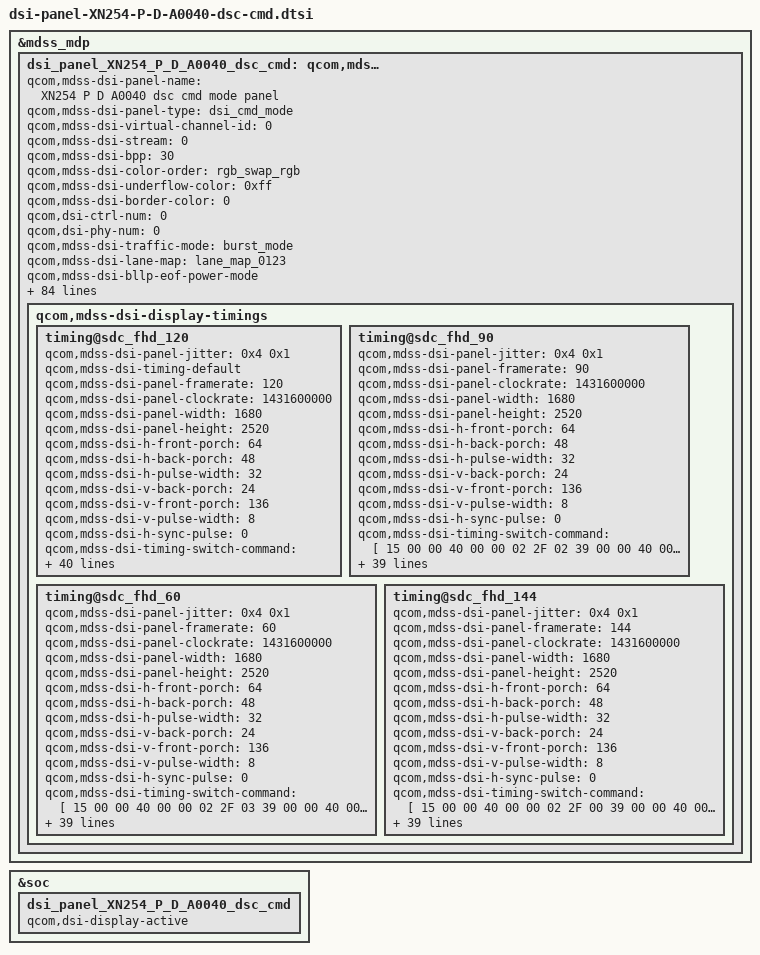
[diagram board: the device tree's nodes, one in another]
&mdss_mdp {
	dsi_panel_XN254_P_D_A0040_dsc_cmd: qcom,mdss_dsi_panel_XN254_P_D_A0040_dsc_cmd {
		qcom,mdss-dsi-panel-name = "XN254 P D A0040 dsc cmd mode panel";
		qcom,mdss-dsi-panel-type = "dsi_cmd_mode";
		qcom,mdss-dsi-virtual-channel-id = <0>;
		qcom,mdss-dsi-stream = <0>;
		qcom,mdss-dsi-bpp = <30>;
		qcom,mdss-dsi-color-order = "rgb_swap_rgb";
		qcom,mdss-dsi-underflow-color = <0xff>;
		qcom,mdss-dsi-border-color = <0>;
		qcom,dsi-ctrl-num = <0>;
		qcom,dsi-phy-num = <0>;
		qcom,mdss-dsi-traffic-mode = "burst_mode";
		qcom,mdss-dsi-lane-map = "lane_map_0123";
		qcom,mdss-dsi-bllp-eof-power-mode;
		qcom,mdss-dsi-bllp-power-mode;
		qcom,mdss-dsi-lane-0-state;
		qcom,mdss-dsi-lane-1-state;
		qcom,mdss-dsi-lane-2-state;
		qcom,mdss-dsi-lane-3-state;
		qcom,mdss-dsi-dma-trigger = "trigger_sw";
		qcom,mdss-dsi-dma-schedule-line = <1>;
		qcom,mdss-dsi-dma-schedule-window = <10>;
		qcom,mdss-dsi-mdp-trigger = "none";
		qcom,mdss-dsi-reset-sequence = <1 2>, <0 5>, <1 25>;
		qcom,mdss-dsi-te-pin-select = <1>;
		qcom,mdss-dsi-te-dcs-command = <1>;
		qcom,mdss-pan-physical-width-dimension = <124>;
		qcom,mdss-pan-physical-height-dimension = <186>;
		qcom,mdss-dsi-init-delay-us = <1000>;
		qcom,mdss-dsi-te-check-enable;
		qcom,mdss-dsi-te-using-te-pin;
		//qcom,mdss-dsi-lp11-init;
		qcom,mdss-dsi-wr-mem-start = <0x2c>;
		qcom,mdss-dsi-wr-mem-continue = <0x3c>;
		qcom,mdss-dsi-panel-jitter = <0x4 0x1>;
		qcom,mdss-bl-high2bit;
		/* HDR Setting */
		//qcom,mdss-dsi-panel-hdr-enabled;
		//qcom,mdss-dsi-panel-hdr-color-primaries = <15635 16450 34000 16000 13250 34500 7500 3000>;
		//update for [MPC15]android.mediapc.cts.PerformanceClassTest#testDisplayHdr pass
		//qcom,mdss-dsi-panel-peak-brightness = <5400000>;
		//qcom,mdss-dsi-panel-peak-brightness = <20000000>;
		//qcom,mdss-dsi-panel-average-brightness = <2000000>;
		//qcom,mdss-dsi-panel-blackness-level = <4000>;


		qcom,mdss-dsi-display-timings {
			timing@sdc_fhd_120 {
				#include "dsi-panel-XN254-P-D-A0040-loading-effect.dtsi"
				//qcom,mdss-mdp-transfer-time-us = <6900>;
				qcom,mdss-dsi-panel-jitter = <0x4 0x1>;
				qcom,mdss-dsi-timing-default;
				qcom,mdss-dsi-panel-framerate = <120>;
				qcom,mdss-dsi-panel-clockrate = <1431600000>;
				qcom,mdss-dsi-panel-width = <1680>;
				qcom,mdss-dsi-panel-height = <2520>;

				qcom,mdss-dsi-h-front-porch = <64>;
				qcom,mdss-dsi-h-back-porch = <48>;
				qcom,mdss-dsi-h-pulse-width = <32>;
				qcom,mdss-dsi-v-back-porch = <24>;
				qcom,mdss-dsi-v-front-porch = <136>;
				qcom,mdss-dsi-v-pulse-width = <8>;
				qcom,mdss-dsi-h-sync-pulse = <0>;

				qcom,mdss-dsi-timing-switch-command = [
					15 00 00 40 00 00 02 2F 01
					39 00 00 40 00 00 06 F0 55 AA 52 08 00
					15 00 00 40 00 00 02 6F 41
					15 00 00 00 00 00 02 BE 4B
				];

				qcom,mdss-dsi-timing-switch-v2-command = [
					15 00 00 40 00 00 02 2F 01
					39 00 00 40 00 00 06 F0 55 AA 52 08 00
					15 00 00 40 00 00 02 6F 41
					15 00 00 40 00 00 02 BE 4B
					39 00 00 40 00 00 06 F0 55 AA 52 08 08
					15 00 00 40 00 00 02 6F 10
					39 00 00 40 00 00 11 B7 00 00 00 00 00 00 00 00 00 00 00 00 05 DC 05 DC
					15 00 00 40 00 00 02 6F 20
					39 00 00 00 00 00 0F B7 06 FE 06 FE 07 58 07 58 07 A8 07 A8 08 00
				];

				qcom,mdss-dsi-on-command = [
					39 00 00 40 00 00 06 F0 55 AA 52 08 01
					39 00 00 40 00 00 06 C5 01 06 06 06 06
					39 00 00 40 00 00 06 F0 55 AA 52 08 01
					15 00 00 40 00 00 02 6F 03
					15 00 00 40 00 00 02 C4 44
					39 00 00 40 00 00 05 FF AA 55 A5 80
					15 00 00 40 00 00 02 6F 29
					39 00 00 40 00 00 03 F8 0E 25
					39 00 00 40 00 00 05 FF AA 55 A5 80
					15 00 00 40 00 00 02 6F 0D
					39 00 00 40 00 00 03 F8 01 89
					39 00 00 40 00 00 06 F0 55 AA 52 08 04
					15 00 00 40 00 00 02 C0 20
					15 00 00 40 00 00 02 C2 12
					15 00 00 40 00 00 02 6F 01
					39 00 00 40 00 00 03 B5 00 00
					15 00 00 40 00 00 02 6F 03
					15 00 00 40 00 00 02 B5 07
					15 00 00 40 00 00 02 6F 00
					39 00 00 40 00 00 04 B8 3A 00 00
					15 00 00 40 00 00 02 6F 03
					39 00 00 40 00 00 03 B8 FF DC
					15 00 00 40 00 00 02 6F 05
					39 00 00 40 00 00 04 B8 3B 00 00
					15 00 00 40 00 00 02 6F 08
					39 00 00 40 00 00 03 B8 FF DC
					15 00 00 40 00 00 02 6F 0A
					39 00 00 40 00 00 04 B8 3C 00 00
					15 00 00 40 00 00 02 6F 0D
					39 00 00 40 00 00 03 B8 FF DC
					15 00 00 40 00 00 02 C0 20
					15 00 00 00 1E 00 02 9D AA
					39 00 00 40 00 00 06 F0 55 AA 52 08 00
					15 00 00 40 00 00 02 6F 31
					39 00 00 40 00 00 05 C0 32 60 04 57
					15 00 00 40 00 00 02 6F 01
					15 00 00 40 00 00 02 C7 01
					15 00 00 40 00 00 02 6F 04
					15 00 00 40 00 00 02 C7 88
					39 00 00 40 00 00 06 F0 55 AA 52 08 03
					15 00 00 40 00 00 02 6F 04
					15 00 00 40 00 00 02 C7 FD
					39 00 00 40 00 00 06 F0 55 AA 52 08 04
					15 00 00 40 00 00 02 C2 12
					15 00 00 40 00 00 02 6F 01
					39 00 00 40 00 00 03 B5 00 14
					15 00 00 40 00 00 02 6F 0C
					39 00 00 40 00 00 04 B6 00 00 00
					15 00 00 40 00 00 02 6F 0F
					39 00 00 40 00 00 04 B6 1C AB 80
					15 00 00 40 00 00 02 6F 18
					39 00 00 40 00 00 04 B6 1D 00 00
					15 00 00 40 00 00 02 6F 1B
					39 00 00 40 00 00 04 B6 07 C8 60
					15 00 00 40 00 00 02 6F 03
					15 00 00 40 00 00 02 B5 83
					15 00 00 40 00 00 02 6F 00
					39 00 00 40 00 00 04 B8 25 00 00
					15 00 00 40 00 00 02 6F 03
					39 00 00 40 00 00 03 B8 01 0C
					15 00 00 40 00 00 02 6F 05
					39 00 00 40 00 00 04 B8 25 10 00
					15 00 00 40 00 00 02 6F 08
					39 00 00 40 00 00 03 B8 03 FD
					15 00 00 40 00 00 02 6F 0a
					39 00 00 40 00 00 04 B8 25 20 00
					15 00 00 40 00 00 02 6F 0d
					39 00 00 40 00 00 03 B8 00 4F
					15 00 00 40 00 00 02 6F 0f
					39 00 00 40 00 00 04 B8 25 30 00
					15 00 00 40 00 00 02 6F 12
					39 00 00 40 00 00 03 B8 00 4F
					15 00 00 40 00 00 02 6F 14
					39 00 00 40 00 00 04 B8 25 40 00
					15 00 00 40 00 00 02 6F 17
					39 00 00 40 00 00 03 B8 03 FD
					15 00 00 40 00 00 02 6F 23
					39 00 00 40 00 00 04 B8 3E 00 00
					15 00 00 40 00 00 02 6F 26
					39 00 00 40 00 00 03 B8 01 61
					39 00 00 40 00 00 03 81 01 19
					15 00 00 40 00 00 02 17 30
					15 00 00 40 00 00 02 26 00
					15 00 00 40 00 00 02 2F 01
					39 00 00 40 00 00 05 2A 00 00 06 8F
					39 00 00 40 00 00 05 2B 00 00 09 D7
					15 00 00 40 00 00 02 35 00
					15 00 00 40 00 00 02 53 20
					39 00 00 40 00 00 03 51 0D BB
					15 00 00 40 00 00 02 6F 04
					39 00 00 40 00 00 03 51 0D BB
					39 00 00 40 00 00 03 51 00 00
					15 00 00 40 00 00 02 6F 04
					39 00 00 40 00 00 03 51 00 00
					15 00 00 40 00 00 02 6F 08
					15 00 00 40 00 00 02 51 00
					15 00 00 40 00 00 02 90 03
					15 00 00 40 00 00 02 6F 01
					15 00 00 40 00 00 02 90 43
					39 00 00 40 00 00 13 91 AB A8 00 18 C2 00 02 A4 02 CD 00 0B 04 2D 02 BA 10 F0
					39 00 00 40 00 00 06 F0 55 AA 52 08 01
					15 00 00 40 00 00 02 6F 02
					39 00 00 00 00 00 03 C7 00 00
					39 00 00 40 00 00 06 F0 55 AA 52 08 08
					15 00 00 40 00 00 02 B0 03
					39 00 00 40 00 00 05 FF AA 55 A5 81
					15 00 00 40 00 00 02 6F 0A
					15 00 00 40 00 00 02 FD 00
					39 00 00 40 00 00 06 F0 55 AA 52 08 00
					39 00 00 40 00 00 05 BE 47 40 4B 40
					15 00 00 40 00 00 02 6F 26
					39 00 00 40 00 00 08 44 00 01 00 01 02 0A 80
					15 00 00 40 00 00 02 6F 4F
					39 00 00 40 00 00 06 44 0A 7F 00 00 00
					15 00 00 40 00 00 02 6F 63
					15 00 00 40 00 00 02 44 66
					15 00 00 40 00 00 02 6F 15
					15 00 00 40 00 00 02 35 60
					15 00 00 40 00 00 02 6F 16
					15 00 00 40 00 00 02 35 E3
					15 00 00 40 00 00 02 A2 07
					39 00 00 40 00 00 06 F0 55 AA 52 08 00
					15 00 00 40 00 00 02 6F 03
					15 00 00 40 00 00 02 B5 E5
					39 00 00 40 00 00 06 F0 55 AA 52 08 00
					15 00 00 40 00 00 02 6F 5C
					15 00 00 40 00 00 02 D5 04
					15 00 00 40 00 00 02 6F 5D
					39 00 00 40 00 00 07 D5 04 05 07 02 00 00
					15 00 00 40 00 00 02 6F 63
					39 00 00 40 00 00 07 D5 1D 28 59 D0 00 00
					39 00 00 40 00 00 06 F0 55 AA 52 08 07
					15 00 00 40 00 00 02 C0 00
					39 00 00 40 00 00 06 F0 55 AA 52 08 01
					39 00 00 40 00 00 05 D9 C8 10 11 40
					39 00 00 40 00 00 06 F0 55 AA 52 08 08
					15 00 00 40 00 00 02 6F 1C
					39 00 00 40 00 00 09 BF 10 10 00 10 00 00 00 00
					15 00 00 40 00 00 02 6F 24
					39 00 00 40 00 00 09 BF 84 84 80 08 00 00 00 00
					15 00 00 40 00 00 02 6F C1
					39 00 00 40 00 00 09 BF 0F 10 10 13 14 00 00 00
					39 00 00 40 00 00 06 F0 55 AA 52 08 08
					39 00 00 40 00 00 05 E0 01 01 01 01
					15 00 00 40 00 00 02 6F 06
					39 00 00 40 00 00 0E E0 00 00 21 32 43 54 65 76 87 98 99 99 99
					39 00 00 40 00 00 0F E1 04 04 03 03 02 02 02 02 02 00 00 00 02 02
					15 00 00 40 00 00 02 6F 0E
					39 00 00 40 00 00 0F E1 05 0A 0E 10 10 10 07 05 07 07 09 05 05 05
					15 00 00 40 00 00 02 6F 1C
					39 00 00 40 00 00 0F E1 00 00 01 01 01 01 01 01 02 02 02 14 11 03
					15 00 00 40 00 00 02 6F 2A
					39 00 00 40 00 00 0F E1 01 02 0E 05 05 05 05 05 04 02 00 01 02 06
					15 00 00 40 00 00 02 6F 38
					39 00 00 40 00 00 0F E1 03 03 02 02 03 02 03 03 02 01 01 03 07 02
					15 00 00 40 00 00 02 6F 46
					39 00 00 40 00 00 0F E1 01 02 05 05 02 02 02 01 01 02 03 03 0A 09
					15 00 00 40 00 00 02 6F 54
					39 00 00 40 00 00 0F E1 01 02 02 03 03 02 02 02 01 01 01 01 0D 00
					15 00 00 40 00 00 02 6F 62
					39 00 00 40 00 00 0F E1 01 02 02 03 04 04 04 03 02 02 03 02 13 03
					15 00 00 40 00 00 02 6F 70
					39 00 00 40 00 00 0F E1 01 02 02 02 02 06 04 05 08 02 02 14 03 03
					39 00 00 40 00 00 0F E2 0A 14 1D 27 27 27 27 27 37 30 28 1C 1C 1C
					15 00 00 40 00 00 02 6F 0E
					39 00 00 40 00 00 0F E2 06 0D 14 1A 1C 1E 2D 2D 1B 1B 11 11 09 09
					15 00 00 40 00 00 02 6F 1C
					39 00 00 40 00 00 0F E2 03 01 04 05 04 04 03 02 03 03 03 14 14 05
					15 00 00 40 00 00 02 6F 2A
					39 00 00 40 00 00 0F E2 06 10 12 13 14 14 0B 0A 0A 05 05 05 06 08
					15 00 00 40 00 00 02 6F 38
					39 00 00 40 00 00 0F E2 04 09 08 09 09 0A 0A 05 05 03 03 04 0B 09
					15 00 00 40 00 00 02 6F 46
					39 00 00 40 00 00 0F E2 06 08 0A 0A 08 06 04 03 01 02 03 05 0C 0C
					15 00 00 40 00 00 02 6F 54
					39 00 00 40 00 00 0F E2 05 09 07 07 06 06 05 03 02 02 03 02 0C 02
					15 00 00 40 00 00 02 6F 62
					39 00 00 40 00 00 0F E2 06 08 08 06 07 06 05 04 03 03 04 04 14 03
					15 00 00 40 00 00 02 6F 70
					39 00 00 40 00 00 0F E2 03 01 02 05 04 05 05 05 08 03 03 14 05 05
					39 00 00 40 00 00 0F E3 05 0A 0F 14 14 14 14 14 14 14 20 0A 0A 0A
					15 00 00 40 00 00 02 6F 0E
					39 00 00 40 00 00 0F E3 03 06 09 0C 0C 0A 04 04 06 04 06 0A 0B 0B
					15 00 00 40 00 00 02 6F 1C
					39 00 00 40 00 00 0F E3 00 00 01 01 01 00 00 00 00 01 02 14 10 03
					15 00 00 40 00 00 02 6F 2A
					39 00 00 40 00 00 0F E3 00 00 0D 00 00 00 00 00 00 03 06 00 04 05
					15 00 00 40 00 00 02 6F 38
					39 00 00 40 00 00 0F E3 03 02 02 02 04 04 04 04 01 01 01 03 06 05
					15 00 00 40 00 00 02 6F 46
					39 00 00 40 00 00 0F E3 00 00 03 02 00 00 00 00 00 02 06 06 0D 08
					15 00 00 40 00 00 02 6F 54
					39 00 00 40 00 00 0F E3 00 00 00 00 00 00 00 00 00 01 01 01 0C 00
					15 00 00 40 00 00 02 6F 62
					39 00 00 40 00 00 0F E3 00 01 01 02 02 02 02 02 02 02 01 01 14 02
					15 00 00 40 00 00 02 6F 70
					39 00 00 40 00 00 0F E3 00 01 03 03 03 06 07 07 05 01 02 14 02 03
					39 00 00 40 00 00 06 F0 55 AA 52 08 01
					15 00 00 40 00 00 02 6F 06
					15 00 00 40 00 00 02 DD D8
					15 00 00 40 00 00 02 6F 0B
					39 00 00 00 00 00 05 DD 08 DC 08 DC
					39 00 00 40 00 00 06 F0 55 AA 52 08 04
					15 00 00 40 00 00 02 6F 06
					15 00 00 40 00 00 02 B5 00
					39 00 00 40 00 00 05 FF AA 55 A5 81
					15 00 00 40 00 00 02 6F 0C
					15 00 00 40 00 00 02 FD 40
					39 00 00 40 00 00 07 51 00 00 00 00 00 00
					39 00 00 40 00 00 06 A3 83 44 83 C4 83
					39 00 00 40 00 00 06 F0 55 AA 52 08 01
					15 00 00 40 00 00 02 6F 20
					39 00 00 40 00 00 04 D9 C0 C8 11
					39 00 00 40 00 00 06 F0 55 AA 52 08 01
					15 00 00 40 00 00 02 6F 02
					15 00 00 40 00 00 02 E7 8C
					15 00 00 40 00 00 02 6F 07
					15 00 00 40 00 00 02 E7 8C
					15 00 00 40 00 00 02 6F 0C
					15 00 00 40 00 00 02 E7 88
					15 00 00 40 00 00 02 6F 11
					15 00 00 40 00 00 02 E7 00
					39 00 00 40 00 00 06 F0 55 AA 52 08 05
					39 00 00 40 00 00 05 E0 02 00 00 01
					39 00 00 40 00 00 05 E1 02 00 00 00
					05 00 00 00 78 00 01 11
					39 00 00 40 00 00 06 A3 83 44 83 C4 83
					15 00 00 40 00 00 02 6f 05
					39 00 00 40 00 00 0E A3 02 04 B5 02 03 00 06 00 00 00 00 00 00
					15 00 00 40 00 00 02 6f 12
					39 00 00 40 00 00 0E A3 01 00 9D 00 00 AA 00 00 00 00 00 00 00
					15 00 00 40 00 00 02 6f A1
					39 00 00 40 00 00 0E A3 02 04 B5 02 03 00 18 00 00 00 00 00 00
					15 00 00 40 00 00 02 6f AE
					39 00 00 40 00 00 07 A3 01 00 9D 00 00 AA
					05 00 00 00 00 00 01 29
				];
				qcom,mdss-dsi-off-command = [
					15 00 00 00 0A 00 02 28 00
					15 00 00 00 78 00 02 10 00
				];
				qcom,dsi-panel-date-switch-command = [
					/*read panel info switch page 3*/
					39 00 00 00 00 00 06 F0 55 AA 52 08 03
				];
				qcom,mdss-dsi-default-switch-page-command = [
					39 00 00 00 00 00 06 F0 55 AA 52 08 00
				];
				qcom,mdss-dsi-lp1-command = [
					39 00 00 40 00 00 06 F0 55 AA 52 08 00
					05 00 00 40 00 00 01 39
					15 00 00 40 00 00 02 6F 04
					39 00 00 00 00 00 03 51 0D BB
				];
				qcom,mdss-dsi-nolp-command = [
					39 00 00 40 00 00 06 F0 55 AA 52 08 00
					05 00 00 40 00 00 01 38
					39 00 00 00 00 00 03 51 00 00
				];
				qcom,mdss-dsi-aod-high-mode-command = [
					39 00 00 40 00 00 06 F0 55 AA 52 08 00
					15 00 00 40 00 00 02 6F 04
					39 00 00 00 00 00 03 51 0D BB
				];
				qcom,mdss-dsi-aod-low-mode-command = [
					39 00 00 40 00 00 06 F0 55 AA 52 08 00
					15 00 00 40 00 00 02 6F 04
					39 00 00 00 00 00 03 51 00 03
				];

				qcom,mdss-dsi-timing-switch-command-state = "dsi_lp_mode";
				qcom,mdss-dsi-on-command-state = "dsi_lp_mode";
				qcom,mdss-dsi-off-command-state = "dsi_lp_mode";
				qcom,dsi-panel-date-switch-command-state = "dsi_lp_mode";
				qcom,mdss-dsi-default-switch-page-command-state = "dsi_lp_mode";

				qcom,compression-mode = "dsc";
				qcom,mdss-dsc-version = <0x12>;
				qcom,mdss-dsc-encoders = <1>;
				qcom,mdss-dsc-slice-height = <24>;
				qcom,mdss-dsc-slice-width = <840>;
				qcom,mdss-dsc-slice-per-pkt = <2>;
				qcom,mdss-dsc-bit-per-component = <10>;
				qcom,mdss-dsc-bit-per-pixel = <8>;
				qcom,mdss-dsc-block-prediction-enable;
			};

			timing@sdc_fhd_90 {
				#include "dsi-panel-XN254-P-D-A0040-loading-effect.dtsi"
				//qcom,mdss-mdp-transfer-time-us = <6900>;
				qcom,mdss-dsi-panel-jitter = <0x4 0x1>;
				qcom,mdss-dsi-panel-framerate = <90>;
				qcom,mdss-dsi-panel-clockrate = <1431600000>;
				qcom,mdss-dsi-panel-width = <1680>;
				qcom,mdss-dsi-panel-height = <2520>;

				qcom,mdss-dsi-h-front-porch = <64>;
				qcom,mdss-dsi-h-back-porch = <48>;
				qcom,mdss-dsi-h-pulse-width = <32>;
				qcom,mdss-dsi-v-back-porch = <24>;
				qcom,mdss-dsi-v-front-porch = <136>;
				qcom,mdss-dsi-v-pulse-width = <8>;
				qcom,mdss-dsi-h-sync-pulse = <0>;

				qcom,mdss-dsi-timing-switch-command = [
					15 00 00 40 00 00 02 2F 02
					39 00 00 40 00 00 06 F0 55 AA 52 08 00
					15 00 00 40 00 00 02 6F 41
					15 00 00 00 00 00 02 BE 40
				];

				qcom,mdss-dsi-timing-switch-v2-command = [
					15 00 00 40 00 00 02 2F 02
					39 00 00 40 00 00 06 F0 55 AA 52 08 00
					15 00 00 40 00 00 02 6F 41
					15 00 00 40 00 00 02 BE 40
					39 00 00 40 00 00 06 F0 55 AA 52 08 08
					15 00 00 40 00 00 02 6F 10
					39 00 00 40 00 00 11 B7 00 00 00 00 00 00 00 00 00 00 00 00 05 DC 05 DC
					15 00 00 40 00 00 02 6F 20
					39 00 00 00 00 00 0F B7 06 FE 06 FE 07 58 07 58 07 A8 07 A8 08 00
				];

				qcom,mdss-dsi-on-command = [
					39 00 00 40 00 00 06 F0 55 AA 52 08 01
					39 00 00 40 00 00 06 C5 01 06 06 06 06
					39 00 00 40 00 00 06 F0 55 AA 52 08 01
					15 00 00 40 00 00 02 6F 03
					15 00 00 40 00 00 02 C4 44
					39 00 00 40 00 00 05 FF AA 55 A5 80
					15 00 00 40 00 00 02 6F 29
					39 00 00 40 00 00 03 F8 0E 25
					39 00 00 40 00 00 05 FF AA 55 A5 80
					15 00 00 40 00 00 02 6F 0D
					39 00 00 40 00 00 03 F8 01 89
					39 00 00 40 00 00 06 F0 55 AA 52 08 04
					15 00 00 40 00 00 02 C0 20
					15 00 00 40 00 00 02 C2 12
					15 00 00 40 00 00 02 6F 01
					39 00 00 40 00 00 03 B5 00 00
					15 00 00 40 00 00 02 6F 03
					15 00 00 40 00 00 02 B5 07
					15 00 00 40 00 00 02 6F 00
					39 00 00 40 00 00 04 B8 3A 00 00
					15 00 00 40 00 00 02 6F 03
					39 00 00 40 00 00 03 B8 FF DC
					15 00 00 40 00 00 02 6F 05
					39 00 00 40 00 00 04 B8 3B 00 00
					15 00 00 40 00 00 02 6F 08
					39 00 00 40 00 00 03 B8 FF DC
					15 00 00 40 00 00 02 6F 0A
					39 00 00 40 00 00 04 B8 3C 00 00
					15 00 00 40 00 00 02 6F 0D
					39 00 00 40 00 00 03 B8 FF DC
					15 00 00 40 00 00 02 C0 20
					15 00 00 00 1E 00 02 9D AA
					39 00 00 40 00 00 06 F0 55 AA 52 08 00
					15 00 00 40 00 00 02 6F 31
					39 00 00 40 00 00 05 C0 32 60 04 57
					15 00 00 40 00 00 02 6F 01
					15 00 00 40 00 00 02 C7 01
					15 00 00 40 00 00 02 6F 04
					15 00 00 40 00 00 02 C7 88
					39 00 00 40 00 00 06 F0 55 AA 52 08 03
					15 00 00 40 00 00 02 6F 04
					15 00 00 40 00 00 02 C7 FD
					39 00 00 40 00 00 06 F0 55 AA 52 08 04
					15 00 00 40 00 00 02 C2 12
					15 00 00 40 00 00 02 6F 01
					39 00 00 40 00 00 03 B5 00 14
					15 00 00 40 00 00 02 6F 0C
					39 00 00 40 00 00 04 B6 00 00 00
					15 00 00 40 00 00 02 6F 0F
					39 00 00 40 00 00 04 B6 1C AB 80
					15 00 00 40 00 00 02 6F 18
					39 00 00 40 00 00 04 B6 1D 00 00
					15 00 00 40 00 00 02 6F 1B
					39 00 00 40 00 00 04 B6 07 C8 60
					15 00 00 40 00 00 02 6F 03
					15 00 00 40 00 00 02 B5 83
					15 00 00 40 00 00 02 6F 00
					39 00 00 40 00 00 04 B8 25 00 00
					15 00 00 40 00 00 02 6F 03
					39 00 00 40 00 00 03 B8 01 0C
					15 00 00 40 00 00 02 6F 05
					39 00 00 40 00 00 04 B8 25 10 00
					15 00 00 40 00 00 02 6F 08
					39 00 00 40 00 00 03 B8 03 FD
					15 00 00 40 00 00 02 6F 0a
					39 00 00 40 00 00 04 B8 25 20 00
					15 00 00 40 00 00 02 6F 0d
					39 00 00 40 00 00 03 B8 00 4F
					15 00 00 40 00 00 02 6F 0f
					39 00 00 40 00 00 04 B8 25 30 00
					15 00 00 40 00 00 02 6F 12
					39 00 00 40 00 00 03 B8 00 4F
					15 00 00 40 00 00 02 6F 14
					39 00 00 40 00 00 04 B8 25 40 00
					15 00 00 40 00 00 02 6F 17
					39 00 00 40 00 00 03 B8 03 FD
					15 00 00 40 00 00 02 6F 23
					39 00 00 40 00 00 04 B8 3E 00 00
					15 00 00 40 00 00 02 6F 26
					39 00 00 40 00 00 03 B8 01 61
					39 00 00 40 00 00 03 81 01 19
					15 00 00 40 00 00 02 17 30
					15 00 00 40 00 00 02 26 00
					15 00 00 40 00 00 02 2F 02
					39 00 00 40 00 00 05 2A 00 00 06 8F
					39 00 00 40 00 00 05 2B 00 00 09 D7
					15 00 00 40 00 00 02 35 00
					15 00 00 40 00 00 02 53 20
					39 00 00 40 00 00 03 51 0D BB
					15 00 00 40 00 00 02 6F 04
					39 00 00 40 00 00 03 51 0D BB
					39 00 00 40 00 00 03 51 00 00
					15 00 00 40 00 00 02 6F 04
					39 00 00 40 00 00 03 51 00 00
					15 00 00 40 00 00 02 6F 08
					15 00 00 40 00 00 02 51 00
					15 00 00 40 00 00 02 90 03
					15 00 00 40 00 00 02 6F 01
					15 00 00 40 00 00 02 90 43
					39 00 00 40 00 00 13 91 AB A8 00 18 C2 00 02 A4 02 CD 00 0B 04 2D 02 BA 10 F0
					39 00 00 40 00 00 06 F0 55 AA 52 08 01
					15 00 00 40 00 00 02 6F 02
					39 00 00 00 00 00 03 C7 00 00
					39 00 00 40 00 00 06 F0 55 AA 52 08 08
					15 00 00 40 00 00 02 B0 03
					39 00 00 40 00 00 05 FF AA 55 A5 81
					15 00 00 40 00 00 02 6F 0A
					15 00 00 40 00 00 02 FD 00
					39 00 00 40 00 00 06 F0 55 AA 52 08 00
					39 00 00 40 00 00 05 BE 47 40 4B 40
					15 00 00 40 00 00 02 6F 26
					39 00 00 40 00 00 08 44 00 01 00 01 02 0A 80
					15 00 00 40 00 00 02 6F 4F
					39 00 00 40 00 00 06 44 0A 7F 00 00 00
					15 00 00 40 00 00 02 6F 63
					15 00 00 40 00 00 02 44 66
					15 00 00 40 00 00 02 6F 15
					15 00 00 40 00 00 02 35 60
					15 00 00 40 00 00 02 6F 16
					15 00 00 40 00 00 02 35 E3
					15 00 00 40 00 00 02 A2 07
					39 00 00 40 00 00 06 F0 55 AA 52 08 00
					15 00 00 40 00 00 02 6F 03
					15 00 00 40 00 00 02 B5 E5
					39 00 00 40 00 00 06 F0 55 AA 52 08 00
					15 00 00 40 00 00 02 6F 5C
					15 00 00 40 00 00 02 D5 04
					15 00 00 40 00 00 02 6F 5D
					39 00 00 40 00 00 07 D5 04 05 07 02 00 00
					15 00 00 40 00 00 02 6F 63
					39 00 00 40 00 00 07 D5 1D 28 59 D0 00 00
					39 00 00 40 00 00 06 F0 55 AA 52 08 07
					15 00 00 40 00 00 02 C0 00
					39 00 00 40 00 00 06 F0 55 AA 52 08 01
					39 00 00 40 00 00 05 D9 C8 10 11 40
					39 00 00 40 00 00 06 F0 55 AA 52 08 08
					15 00 00 40 00 00 02 6F 1C
					39 00 00 40 00 00 09 BF 10 10 00 10 00 00 00 00
					15 00 00 40 00 00 02 6F 24
					39 00 00 40 00 00 09 BF 84 84 80 08 00 00 00 00
					15 00 00 40 00 00 02 6F C1
					39 00 00 40 00 00 09 BF 0F 10 10 13 14 00 00 00
					39 00 00 40 00 00 06 F0 55 AA 52 08 08
					39 00 00 40 00 00 05 E0 01 01 01 01
					15 00 00 40 00 00 02 6F 06
					39 00 00 40 00 00 0E E0 00 00 21 32 43 54 65 76 87 98 99 99 99
					39 00 00 40 00 00 0F E1 04 04 03 03 02 02 02 02 02 00 00 00 02 02
					15 00 00 40 00 00 02 6F 0E
					39 00 00 40 00 00 0F E1 05 0A 0E 10 10 10 07 05 07 07 09 05 05 05
					15 00 00 40 00 00 02 6F 1C
					39 00 00 40 00 00 0F E1 00 00 01 01 01 01 01 01 02 02 02 14 11 03
					15 00 00 40 00 00 02 6F 2A
					39 00 00 40 00 00 0F E1 01 02 0E 05 05 05 05 05 04 02 00 01 02 06
					15 00 00 40 00 00 02 6F 38
					39 00 00 40 00 00 0F E1 03 03 02 02 03 02 03 03 02 01 01 03 07 02
					15 00 00 40 00 00 02 6F 46
					39 00 00 40 00 00 0F E1 01 02 05 05 02 02 02 01 01 02 03 03 0A 09
					15 00 00 40 00 00 02 6F 54
					39 00 00 40 00 00 0F E1 01 02 02 03 03 02 02 02 01 01 01 01 0D 00
					15 00 00 40 00 00 02 6F 62
					39 00 00 40 00 00 0F E1 01 02 02 03 04 04 04 03 02 02 03 02 13 03
					15 00 00 40 00 00 02 6F 70
					39 00 00 40 00 00 0F E1 01 02 02 02 02 06 04 05 08 02 02 14 03 03
					39 00 00 40 00 00 0F E2 0A 14 1D 27 27 27 27 27 37 30 28 1C 1C 1C
					15 00 00 40 00 00 02 6F 0E
					39 00 00 40 00 00 0F E2 06 0D 14 1A 1C 1E 2D 2D 1B 1B 11 11 09 09
					15 00 00 40 00 00 02 6F 1C
					39 00 00 40 00 00 0F E2 03 01 04 05 04 04 03 02 03 03 03 14 14 05
					15 00 00 40 00 00 02 6F 2A
					39 00 00 40 00 00 0F E2 06 10 12 13 14 14 0B 0A 0A 05 05 05 06 08
					15 00 00 40 00 00 02 6F 38
					39 00 00 40 00 00 0F E2 04 09 08 09 09 0A 0A 05 05 03 03 04 0B 09
					15 00 00 40 00 00 02 6F 46
					39 00 00 40 00 00 0F E2 06 08 0A 0A 08 06 04 03 01 02 03 05 0C 0C
					15 00 00 40 00 00 02 6F 54
					39 00 00 40 00 00 0F E2 05 09 07 07 06 06 05 03 02 02 03 02 0C 02
					15 00 00 40 00 00 02 6F 62
					39 00 00 40 00 00 0F E2 06 08 08 06 07 06 05 04 03 03 04 04 14 03
					15 00 00 40 00 00 02 6F 70
					39 00 00 40 00 00 0F E2 03 01 02 05 04 05 05 05 08 03 03 14 05 05
					39 00 00 40 00 00 0F E3 05 0A 0F 14 14 14 14 14 14 14 20 0A 0A 0A
					15 00 00 40 00 00 02 6F 0E
					39 00 00 40 00 00 0F E3 03 06 09 0C 0C 0A 04 04 06 04 06 0A 0B 0B
					15 00 00 40 00 00 02 6F 1C
					39 00 00 40 00 00 0F E3 00 00 01 01 01 00 00 00 00 01 02 14 10 03
					15 00 00 40 00 00 02 6F 2A
					39 00 00 40 00 00 0F E3 00 00 0D 00 00 00 00 00 00 03 06 00 04 05
					15 00 00 40 00 00 02 6F 38
					39 00 00 40 00 00 0F E3 03 02 02 02 04 04 04 04 01 01 01 03 06 05
					15 00 00 40 00 00 02 6F 46
					39 00 00 40 00 00 0F E3 00 00 03 02 00 00 00 00 00 02 06 06 0D 08
					15 00 00 40 00 00 02 6F 54
					39 00 00 40 00 00 0F E3 00 00 00 00 00 00 00 00 00 01 01 01 0C 00
					15 00 00 40 00 00 02 6F 62
					39 00 00 40 00 00 0F E3 00 01 01 02 02 02 02 02 02 02 01 01 14 02
					15 00 00 40 00 00 02 6F 70
					39 00 00 40 00 00 0F E3 00 01 03 03 03 06 07 07 05 01 02 14 02 03
					39 00 00 40 00 00 06 F0 55 AA 52 08 01
					15 00 00 40 00 00 02 6F 06
					15 00 00 40 00 00 02 DD D8
					15 00 00 40 00 00 02 6F 0B
					39 00 00 00 00 00 05 DD 08 DC 08 DC
					39 00 00 40 00 00 06 F0 55 AA 52 08 04
					15 00 00 40 00 00 02 6F 06
					15 00 00 40 00 00 02 B5 00
					39 00 00 40 00 00 05 FF AA 55 A5 81
					15 00 00 40 00 00 02 6F 0C
					15 00 00 40 00 00 02 FD 40
					39 00 00 40 00 00 07 51 00 00 00 00 00 00
					39 00 00 40 00 00 06 A3 83 44 83 C4 83
					39 00 00 40 00 00 06 F0 55 AA 52 08 01
					15 00 00 40 00 00 02 6F 20
					39 00 00 40 00 00 04 D9 C0 C8 11
					39 00 00 40 00 00 06 F0 55 AA 52 08 01
					15 00 00 40 00 00 02 6F 02
					15 00 00 40 00 00 02 E7 8C
					15 00 00 40 00 00 02 6F 07
					15 00 00 40 00 00 02 E7 8C
					15 00 00 40 00 00 02 6F 0C
					15 00 00 40 00 00 02 E7 88
					15 00 00 40 00 00 02 6F 11
					15 00 00 40 00 00 02 E7 00
					39 00 00 40 00 00 06 F0 55 AA 52 08 05
					39 00 00 40 00 00 05 E0 02 00 00 01
					39 00 00 40 00 00 05 E1 02 00 00 00
					05 00 00 00 78 00 01 11
					39 00 00 40 00 00 06 A3 83 44 83 C4 83
					15 00 00 40 00 00 02 6f 05
					39 00 00 40 00 00 0E A3 02 04 B5 02 03 00 06 00 00 00 00 00 00
					15 00 00 40 00 00 02 6f 12
					39 00 00 40 00 00 0E A3 01 00 9D 00 00 AA 00 00 00 00 00 00 00
					15 00 00 40 00 00 02 6f A1
					39 00 00 40 00 00 0E A3 02 04 B5 02 03 00 18 00 00 00 00 00 00
					15 00 00 40 00 00 02 6f AE
					39 00 00 40 00 00 07 A3 01 00 9D 00 00 AA
					05 00 00 00 00 00 01 29
				];
				qcom,mdss-dsi-off-command = [
					15 00 00 00 0A 00 02 28 00
					15 00 00 00 78 00 02 10 00
				];
				qcom,dsi-panel-date-switch-command = [
					/*read panel info switch page 3*/
					39 00 00 00 00 00 06 F0 55 AA 52 08 03
				];
				qcom,mdss-dsi-default-switch-page-command = [
					39 00 00 00 00 00 06 F0 55 AA 52 08 00
				];
				qcom,mdss-dsi-lp1-command = [
					39 00 00 40 00 00 06 F0 55 AA 52 08 00
					05 00 00 40 00 00 01 39
					15 00 00 40 00 00 02 6F 04
					39 00 00 00 00 00 03 51 0D BB
				];
				qcom,mdss-dsi-nolp-command = [
					39 00 00 40 00 00 06 F0 55 AA 52 08 00
					05 00 00 40 00 00 01 38
					39 00 00 00 00 00 03 51 00 00
				];
				qcom,mdss-dsi-aod-high-mode-command = [
					39 00 00 40 00 00 06 F0 55 AA 52 08 00
					15 00 00 40 00 00 02 6F 04
					39 00 00 00 00 00 03 51 0D BB
				];
				qcom,mdss-dsi-aod-low-mode-command = [
					39 00 00 40 00 00 06 F0 55 AA 52 08 00
					15 00 00 40 00 00 02 6F 04
					39 00 00 00 00 00 03 51 00 03
				];

				qcom,mdss-dsi-timing-switch-command-state = "dsi_lp_mode";
				qcom,mdss-dsi-on-command-state = "dsi_lp_mode";
				qcom,mdss-dsi-off-command-state = "dsi_lp_mode";
				qcom,dsi-panel-date-switch-command-state = "dsi_lp_mode";
				qcom,mdss-dsi-default-switch-page-command-state = "dsi_lp_mode";

				qcom,compression-mode = "dsc";
				qcom,mdss-dsc-version = <0x12>;
				qcom,mdss-dsc-encoders = <1>;
				qcom,mdss-dsc-slice-height = <24>;
				qcom,mdss-dsc-slice-width = <840>;
				qcom,mdss-dsc-slice-per-pkt = <2>;
				qcom,mdss-dsc-bit-per-component = <10>;
				qcom,mdss-dsc-bit-per-pixel = <8>;
				qcom,mdss-dsc-block-prediction-enable;
			};

			timing@sdc_fhd_60 {
				#include "dsi-panel-XN254-P-D-A0040-loading-effect.dtsi"
				//qcom,mdss-mdp-transfer-time-us = <6900>;
				qcom,mdss-dsi-panel-jitter = <0x4 0x1>;
				qcom,mdss-dsi-panel-framerate = <60>;
				qcom,mdss-dsi-panel-clockrate = <1431600000>;
				qcom,mdss-dsi-panel-width = <1680>;
				qcom,mdss-dsi-panel-height = <2520>;

				qcom,mdss-dsi-h-front-porch = <64>;
				qcom,mdss-dsi-h-back-porch = <48>;
				qcom,mdss-dsi-h-pulse-width = <32>;
				qcom,mdss-dsi-v-back-porch = <24>;
				qcom,mdss-dsi-v-front-porch = <136>;
				qcom,mdss-dsi-v-pulse-width = <8>;
				qcom,mdss-dsi-h-sync-pulse = <0>;

				qcom,mdss-dsi-timing-switch-command = [
					15 00 00 40 00 00 02 2F 03
					39 00 00 40 00 00 06 F0 55 AA 52 08 00
					15 00 00 40 00 00 02 6F 41
					15 00 00 00 00 00 02 BE 5F
				];

				qcom,mdss-dsi-timing-switch-v2-command = [
					15 00 00 40 00 00 02 2F 03
					39 00 00 40 00 00 06 F0 55 AA 52 08 00
					15 00 00 40 00 00 02 6F 41
					15 00 00 40 00 00 02 BE 5F
					39 00 00 40 00 00 06 F0 55 AA 52 08 08
					15 00 00 40 00 00 02 6F 10
					39 00 00 40 00 00 11 B7 00 00 00 00 00 00 00 00 00 00 00 00 05 DC 05 DC
					15 00 00 40 00 00 02 6F 20
					39 00 00 00 00 00 0F B7 06 FE 06 FE 07 58 07 58 07 A8 07 A8 08 00
				];

				qcom,mdss-dsi-on-command = [
					39 00 00 40 00 00 06 F0 55 AA 52 08 01
					39 00 00 40 00 00 06 C5 01 06 06 06 06
					39 00 00 40 00 00 06 F0 55 AA 52 08 01
					15 00 00 40 00 00 02 6F 03
					15 00 00 40 00 00 02 C4 44
					39 00 00 40 00 00 05 FF AA 55 A5 80
					15 00 00 40 00 00 02 6F 29
					39 00 00 40 00 00 03 F8 0E 25
					39 00 00 40 00 00 05 FF AA 55 A5 80
					15 00 00 40 00 00 02 6F 0D
					39 00 00 40 00 00 03 F8 01 89
					39 00 00 40 00 00 06 F0 55 AA 52 08 04
					15 00 00 40 00 00 02 C0 20
					15 00 00 40 00 00 02 C2 12
					15 00 00 40 00 00 02 6F 01
					39 00 00 40 00 00 03 B5 00 00
					15 00 00 40 00 00 02 6F 03
					15 00 00 40 00 00 02 B5 07
					15 00 00 40 00 00 02 6F 00
					39 00 00 40 00 00 04 B8 3A 00 00
					15 00 00 40 00 00 02 6F 03
					39 00 00 40 00 00 03 B8 FF DC
					15 00 00 40 00 00 02 6F 05
					39 00 00 40 00 00 04 B8 3B 00 00
					15 00 00 40 00 00 02 6F 08
					39 00 00 40 00 00 03 B8 FF DC
					15 00 00 40 00 00 02 6F 0A
					39 00 00 40 00 00 04 B8 3C 00 00
					15 00 00 40 00 00 02 6F 0D
					39 00 00 40 00 00 03 B8 FF DC
					15 00 00 40 00 00 02 C0 20
					15 00 00 00 1E 00 02 9D AA
					39 00 00 40 00 00 06 F0 55 AA 52 08 00
					15 00 00 40 00 00 02 6F 31
					39 00 00 40 00 00 05 C0 32 60 04 57
					15 00 00 40 00 00 02 6F 01
					15 00 00 40 00 00 02 C7 01
					15 00 00 40 00 00 02 6F 04
					15 00 00 40 00 00 02 C7 88
					39 00 00 40 00 00 06 F0 55 AA 52 08 03
					15 00 00 40 00 00 02 6F 04
					15 00 00 40 00 00 02 C7 FD
					39 00 00 40 00 00 06 F0 55 AA 52 08 04
					15 00 00 40 00 00 02 C2 12
					15 00 00 40 00 00 02 6F 01
					39 00 00 40 00 00 03 B5 00 14
					15 00 00 40 00 00 02 6F 0C
					39 00 00 40 00 00 04 B6 00 00 00
					15 00 00 40 00 00 02 6F 0F
					39 00 00 40 00 00 04 B6 1C AB 80
					15 00 00 40 00 00 02 6F 18
					39 00 00 40 00 00 04 B6 1D 00 00
					15 00 00 40 00 00 02 6F 1B
					39 00 00 40 00 00 04 B6 07 C8 60
					15 00 00 40 00 00 02 6F 03
					15 00 00 40 00 00 02 B5 83
					15 00 00 40 00 00 02 6F 00
					39 00 00 40 00 00 04 B8 25 00 00
					15 00 00 40 00 00 02 6F 03
					39 00 00 40 00 00 03 B8 01 0C
					15 00 00 40 00 00 02 6F 05
					39 00 00 40 00 00 04 B8 25 10 00
					15 00 00 40 00 00 02 6F 08
					39 00 00 40 00 00 03 B8 03 FD
					15 00 00 40 00 00 02 6F 0a
					39 00 00 40 00 00 04 B8 25 20 00
					15 00 00 40 00 00 02 6F 0d
					39 00 00 40 00 00 03 B8 00 4F
					15 00 00 40 00 00 02 6F 0f
					39 00 00 40 00 00 04 B8 25 30 00
					15 00 00 40 00 00 02 6F 12
					39 00 00 40 00 00 03 B8 00 4F
					15 00 00 40 00 00 02 6F 14
					39 00 00 40 00 00 04 B8 25 40 00
					15 00 00 40 00 00 02 6F 17
					39 00 00 40 00 00 03 B8 03 FD
					15 00 00 40 00 00 02 6F 23
					39 00 00 40 00 00 04 B8 3E 00 00
					15 00 00 40 00 00 02 6F 26
					39 00 00 40 00 00 03 B8 01 61
					39 00 00 40 00 00 03 81 01 19
					15 00 00 40 00 00 02 17 30
					15 00 00 40 00 00 02 26 00
					15 00 00 40 00 00 02 2F 03
					39 00 00 40 00 00 05 2A 00 00 06 8F
					39 00 00 40 00 00 05 2B 00 00 09 D7
					15 00 00 40 00 00 02 35 00
					15 00 00 40 00 00 02 53 20
					39 00 00 40 00 00 03 51 0D BB
					15 00 00 40 00 00 02 6F 04
					39 00 00 40 00 00 03 51 0D BB
					39 00 00 40 00 00 03 51 00 00
					15 00 00 40 00 00 02 6F 04
					39 00 00 40 00 00 03 51 00 00
					15 00 00 40 00 00 02 6F 08
					15 00 00 40 00 00 02 51 00
					15 00 00 40 00 00 02 90 03
					15 00 00 40 00 00 02 6F 01
					15 00 00 40 00 00 02 90 43
					39 00 00 40 00 00 13 91 AB A8 00 18 C2 00 02 A4 02 CD 00 0B 04 2D 02 BA 10 F0
					39 00 00 40 00 00 06 F0 55 AA 52 08 01
					15 00 00 40 00 00 02 6F 02
					39 00 00 00 00 00 03 C7 00 00
					39 00 00 40 00 00 06 F0 55 AA 52 08 08
					15 00 00 40 00 00 02 B0 03
					39 00 00 40 00 00 05 FF AA 55 A5 81
					15 00 00 40 00 00 02 6F 0A
					15 00 00 40 00 00 02 FD 00
					39 00 00 40 00 00 06 F0 55 AA 52 08 00
					39 00 00 40 00 00 05 BE 47 40 4B 40
					15 00 00 40 00 00 02 6F 26
					39 00 00 40 00 00 08 44 00 01 00 01 02 0A 80
					15 00 00 40 00 00 02 6F 4F
					39 00 00 40 00 00 06 44 0A 7F 00 00 00
					15 00 00 40 00 00 02 6F 63
					15 00 00 40 00 00 02 44 66
					15 00 00 40 00 00 02 6F 15
					15 00 00 40 00 00 02 35 60
					15 00 00 40 00 00 02 6F 16
					15 00 00 40 00 00 02 35 E3
					15 00 00 40 00 00 02 A2 07
					39 00 00 40 00 00 06 F0 55 AA 52 08 00
					15 00 00 40 00 00 02 6F 03
					15 00 00 40 00 00 02 B5 E5
					39 00 00 40 00 00 06 F0 55 AA 52 08 00
					15 00 00 40 00 00 02 6F 5C
					15 00 00 40 00 00 02 D5 04
					15 00 00 40 00 00 02 6F 5D
					39 00 00 40 00 00 07 D5 04 05 07 02 00 00
					15 00 00 40 00 00 02 6F 63
					39 00 00 40 00 00 07 D5 1D 28 59 D0 00 00
					39 00 00 40 00 00 06 F0 55 AA 52 08 07
					15 00 00 40 00 00 02 C0 00
					39 00 00 40 00 00 06 F0 55 AA 52 08 01
					39 00 00 40 00 00 05 D9 C8 10 11 40
					39 00 00 40 00 00 06 F0 55 AA 52 08 08
					15 00 00 40 00 00 02 6F 1C
					39 00 00 40 00 00 09 BF 10 10 00 10 00 00 00 00
					15 00 00 40 00 00 02 6F 24
					39 00 00 40 00 00 09 BF 84 84 80 08 00 00 00 00
					15 00 00 40 00 00 02 6F C1
					39 00 00 40 00 00 09 BF 0F 10 10 13 14 00 00 00
					39 00 00 40 00 00 06 F0 55 AA 52 08 08
					39 00 00 40 00 00 05 E0 01 01 01 01
					15 00 00 40 00 00 02 6F 06
					39 00 00 40 00 00 0E E0 00 00 21 32 43 54 65 76 87 98 99 99 99
					39 00 00 40 00 00 0F E1 04 04 03 03 02 02 02 02 02 00 00 00 02 02
					15 00 00 40 00 00 02 6F 0E
					39 00 00 40 00 00 0F E1 05 0A 0E 10 10 10 07 05 07 07 09 05 05 05
					15 00 00 40 00 00 02 6F 1C
					39 00 00 40 00 00 0F E1 00 00 01 01 01 01 01 01 02 02 02 14 11 03
					15 00 00 40 00 00 02 6F 2A
					39 00 00 40 00 00 0F E1 01 02 0E 05 05 05 05 05 04 02 00 01 02 06
					15 00 00 40 00 00 02 6F 38
					39 00 00 40 00 00 0F E1 03 03 02 02 03 02 03 03 02 01 01 03 07 02
					15 00 00 40 00 00 02 6F 46
					39 00 00 40 00 00 0F E1 01 02 05 05 02 02 02 01 01 02 03 03 0A 09
					15 00 00 40 00 00 02 6F 54
					39 00 00 40 00 00 0F E1 01 02 02 03 03 02 02 02 01 01 01 01 0D 00
					15 00 00 40 00 00 02 6F 62
					39 00 00 40 00 00 0F E1 01 02 02 03 04 04 04 03 02 02 03 02 13 03
					15 00 00 40 00 00 02 6F 70
					39 00 00 40 00 00 0F E1 01 02 02 02 02 06 04 05 08 02 02 14 03 03
					39 00 00 40 00 00 0F E2 0A 14 1D 27 27 27 27 27 37 30 28 1C 1C 1C
					15 00 00 40 00 00 02 6F 0E
					39 00 00 40 00 00 0F E2 06 0D 14 1A 1C 1E 2D 2D 1B 1B 11 11 09 09
					15 00 00 40 00 00 02 6F 1C
					39 00 00 40 00 00 0F E2 03 01 04 05 04 04 03 02 03 03 03 14 14 05
					15 00 00 40 00 00 02 6F 2A
					39 00 00 40 00 00 0F E2 06 10 12 13 14 14 0B 0A 0A 05 05 05 06 08
					15 00 00 40 00 00 02 6F 38
					39 00 00 40 00 00 0F E2 04 09 08 09 09 0A 0A 05 05 03 03 04 0B 09
					15 00 00 40 00 00 02 6F 46
					39 00 00 40 00 00 0F E2 06 08 0A 0A 08 06 04 03 01 02 03 05 0C 0C
					15 00 00 40 00 00 02 6F 54
					39 00 00 40 00 00 0F E2 05 09 07 07 06 06 05 03 02 02 03 02 0C 02
					15 00 00 40 00 00 02 6F 62
					39 00 00 40 00 00 0F E2 06 08 08 06 07 06 05 04 03 03 04 04 14 03
					15 00 00 40 00 00 02 6F 70
					39 00 00 40 00 00 0F E2 03 01 02 05 04 05 05 05 08 03 03 14 05 05
					39 00 00 40 00 00 0F E3 05 0A 0F 14 14 14 14 14 14 14 20 0A 0A 0A
					15 00 00 40 00 00 02 6F 0E
					39 00 00 40 00 00 0F E3 03 06 09 0C 0C 0A 04 04 06 04 06 0A 0B 0B
					15 00 00 40 00 00 02 6F 1C
					39 00 00 40 00 00 0F E3 00 00 01 01 01 00 00 00 00 01 02 14 10 03
					15 00 00 40 00 00 02 6F 2A
					39 00 00 40 00 00 0F E3 00 00 0D 00 00 00 00 00 00 03 06 00 04 05
					15 00 00 40 00 00 02 6F 38
					39 00 00 40 00 00 0F E3 03 02 02 02 04 04 04 04 01 01 01 03 06 05
					15 00 00 40 00 00 02 6F 46
					39 00 00 40 00 00 0F E3 00 00 03 02 00 00 00 00 00 02 06 06 0D 08
					15 00 00 40 00 00 02 6F 54
					39 00 00 40 00 00 0F E3 00 00 00 00 00 00 00 00 00 01 01 01 0C 00
					15 00 00 40 00 00 02 6F 62
					39 00 00 40 00 00 0F E3 00 01 01 02 02 02 02 02 02 02 01 01 14 02
					15 00 00 40 00 00 02 6F 70
					39 00 00 40 00 00 0F E3 00 01 03 03 03 06 07 07 05 01 02 14 02 03
					39 00 00 40 00 00 06 F0 55 AA 52 08 01
					15 00 00 40 00 00 02 6F 06
					15 00 00 40 00 00 02 DD D8
					15 00 00 40 00 00 02 6F 0B
					39 00 00 00 00 00 05 DD 08 DC 08 DC
					39 00 00 40 00 00 06 F0 55 AA 52 08 04
					15 00 00 40 00 00 02 6F 06
					15 00 00 40 00 00 02 B5 00
					39 00 00 40 00 00 05 FF AA 55 A5 81
					15 00 00 40 00 00 02 6F 0C
					15 00 00 40 00 00 02 FD 40
					39 00 00 40 00 00 07 51 00 00 00 00 00 00
					39 00 00 40 00 00 06 A3 83 44 83 C4 83
					39 00 00 40 00 00 06 F0 55 AA 52 08 01
					15 00 00 40 00 00 02 6F 20
					39 00 00 40 00 00 04 D9 C0 C8 11
					39 00 00 40 00 00 06 F0 55 AA 52 08 01
					15 00 00 40 00 00 02 6F 02
					15 00 00 40 00 00 02 E7 8C
					15 00 00 40 00 00 02 6F 07
					15 00 00 40 00 00 02 E7 8C
					15 00 00 40 00 00 02 6F 0C
					15 00 00 40 00 00 02 E7 88
					15 00 00 40 00 00 02 6F 11
					15 00 00 40 00 00 02 E7 00
					39 00 00 40 00 00 06 F0 55 AA 52 08 05
					39 00 00 40 00 00 05 E0 02 00 00 01
					39 00 00 40 00 00 05 E1 02 00 00 00
					05 00 00 00 78 00 01 11
					39 00 00 40 00 00 06 A3 83 44 83 C4 83
					15 00 00 40 00 00 02 6f 05
					39 00 00 40 00 00 0E A3 02 04 B5 02 03 00 06 00 00 00 00 00 00
					15 00 00 40 00 00 02 6f 12
					39 00 00 40 00 00 0E A3 01 00 9D 00 00 AA 00 00 00 00 00 00 00
					15 00 00 40 00 00 02 6f A1
					39 00 00 40 00 00 0E A3 02 04 B5 02 03 00 18 00 00 00 00 00 00
					15 00 00 40 00 00 02 6f AE
					39 00 00 40 00 00 07 A3 01 00 9D 00 00 AA
					05 00 00 00 00 00 01 29
				];
				qcom,mdss-dsi-off-command = [
					15 00 00 00 0A 00 02 28 00
					15 00 00 00 78 00 02 10 00
				];
				qcom,dsi-panel-date-switch-command = [
					/*read panel info switch page 3*/
					39 00 00 00 00 00 06 F0 55 AA 52 08 03
				];
				qcom,mdss-dsi-default-switch-page-command = [
					39 00 00 00 00 00 06 F0 55 AA 52 08 00
				];
				qcom,mdss-dsi-lp1-command = [
					39 00 00 40 00 00 06 F0 55 AA 52 08 00
					05 00 00 40 00 00 01 39
					15 00 00 40 00 00 02 6F 04
					39 00 00 00 00 00 03 51 0D BB
				];
				qcom,mdss-dsi-nolp-command = [
					39 00 00 40 00 00 06 F0 55 AA 52 08 00
					05 00 00 40 00 00 01 38
					39 00 00 00 00 00 03 51 00 00
				];
				qcom,mdss-dsi-aod-high-mode-command = [
					39 00 00 40 00 00 06 F0 55 AA 52 08 00
					15 00 00 40 00 00 02 6F 04
					39 00 00 00 00 00 03 51 0D BB
				];
				qcom,mdss-dsi-aod-low-mode-command = [
					39 00 00 40 00 00 06 F0 55 AA 52 08 00
					15 00 00 40 00 00 02 6F 04
					39 00 00 00 00 00 03 51 00 03
				];
				qcom,mdss-dsi-timing-switch-command-state = "dsi_lp_mode";
				qcom,mdss-dsi-on-command-state = "dsi_lp_mode";
				qcom,mdss-dsi-off-command-state = "dsi_lp_mode";
				qcom,dsi-panel-date-switch-command-state = "dsi_lp_mode";
				qcom,mdss-dsi-default-switch-page-command-state = "dsi_lp_mode";

				qcom,compression-mode = "dsc";
				qcom,mdss-dsc-version = <0x12>;
				qcom,mdss-dsc-encoders = <1>;
				qcom,mdss-dsc-slice-height = <24>;
				qcom,mdss-dsc-slice-width = <840>;
				qcom,mdss-dsc-slice-per-pkt = <2>;
				qcom,mdss-dsc-bit-per-component = <10>;
				qcom,mdss-dsc-bit-per-pixel = <8>;
				qcom,mdss-dsc-block-prediction-enable;
			};

			timing@sdc_fhd_144 {
				#include "dsi-panel-XN254-P-D-A0040-loading-effect.dtsi"
				//qcom,mdss-mdp-transfer-time-us = <6900>;
				qcom,mdss-dsi-panel-jitter = <0x4 0x1>;
				qcom,mdss-dsi-panel-framerate = <144>;
				qcom,mdss-dsi-panel-clockrate = <1431600000>;
				qcom,mdss-dsi-panel-width = <1680>;
				qcom,mdss-dsi-panel-height = <2520>;

				qcom,mdss-dsi-h-front-porch = <64>;
				qcom,mdss-dsi-h-back-porch = <48>;
				qcom,mdss-dsi-h-pulse-width = <32>;
				qcom,mdss-dsi-v-back-porch = <24>;
				qcom,mdss-dsi-v-front-porch = <136>;
				qcom,mdss-dsi-v-pulse-width = <8>;
				qcom,mdss-dsi-h-sync-pulse = <0>;

				qcom,mdss-dsi-timing-switch-command = [
					15 00 00 40 00 00 02 2F 00
					39 00 00 40 00 00 06 F0 55 AA 52 08 00
					15 00 00 40 00 00 02 6F 41
					15 00 00 00 00 00 02 BE 4B
				];

				qcom,mdss-dsi-timing-switch-v2-command = [
					15 00 00 40 00 00 02 2F 00
					39 00 00 40 00 00 06 F0 55 AA 52 08 00
					15 00 00 40 00 00 02 6F 41
					15 00 00 40 00 00 02 BE 4B
					39 00 00 40 00 00 06 F0 55 AA 52 08 08
					15 00 00 40 00 00 02 6F 10
					39 00 00 40 00 00 11 B7 00 00 00 00 00 00 00 00 00 00 00 00 08 CA 08 CA
					15 00 00 40 00 00 02 6F 20
					39 00 00 00 00 00 0F B7 09 38 09 38 09 90 09 90 09 E0 09 E0 09 E0
				];

				qcom,mdss-dsi-on-command = [
					39 00 00 40 00 00 06 F0 55 AA 52 08 01
					39 00 00 40 00 00 06 C5 01 06 06 06 06
					39 00 00 40 00 00 06 F0 55 AA 52 08 01
					15 00 00 40 00 00 02 6F 03
					15 00 00 40 00 00 02 C4 44
					39 00 00 40 00 00 05 FF AA 55 A5 80
					15 00 00 40 00 00 02 6F 29
					39 00 00 40 00 00 03 F8 0E 25
					39 00 00 40 00 00 05 FF AA 55 A5 80
					15 00 00 40 00 00 02 6F 0D
					39 00 00 40 00 00 03 F8 01 89
					39 00 00 40 00 00 06 F0 55 AA 52 08 04
					15 00 00 40 00 00 02 C0 20
					15 00 00 40 00 00 02 C2 12
					15 00 00 40 00 00 02 6F 01
					39 00 00 40 00 00 03 B5 00 00
					15 00 00 40 00 00 02 6F 03
					15 00 00 40 00 00 02 B5 07
					15 00 00 40 00 00 02 6F 00
					39 00 00 40 00 00 04 B8 3A 00 00
					15 00 00 40 00 00 02 6F 03
					39 00 00 40 00 00 03 B8 FF DC
					15 00 00 40 00 00 02 6F 05
					39 00 00 40 00 00 04 B8 3B 00 00
					15 00 00 40 00 00 02 6F 08
					39 00 00 40 00 00 03 B8 FF DC
					15 00 00 40 00 00 02 6F 0A
					39 00 00 40 00 00 04 B8 3C 00 00
					15 00 00 40 00 00 02 6F 0D
					39 00 00 40 00 00 03 B8 FF DC
					15 00 00 40 00 00 02 C0 20
					15 00 00 00 1E 00 02 9D AA
					39 00 00 40 00 00 06 F0 55 AA 52 08 00
					15 00 00 40 00 00 02 6F 31
					39 00 00 40 00 00 05 C0 32 60 04 57
					15 00 00 40 00 00 02 6F 01
					15 00 00 40 00 00 02 C7 01
					15 00 00 40 00 00 02 6F 04
					15 00 00 40 00 00 02 C7 88
					39 00 00 40 00 00 06 F0 55 AA 52 08 03
					15 00 00 40 00 00 02 6F 04
					15 00 00 40 00 00 02 C7 FD
					39 00 00 40 00 00 06 F0 55 AA 52 08 04
					15 00 00 40 00 00 02 C2 12
					15 00 00 40 00 00 02 6F 01
					39 00 00 40 00 00 03 B5 00 14
					15 00 00 40 00 00 02 6F 0C
					39 00 00 40 00 00 04 B6 00 00 00
					15 00 00 40 00 00 02 6F 0F
					39 00 00 40 00 00 04 B6 1C AB 80
					15 00 00 40 00 00 02 6F 18
					39 00 00 40 00 00 04 B6 1D 00 00
					15 00 00 40 00 00 02 6F 1B
					39 00 00 40 00 00 04 B6 07 C8 60
					15 00 00 40 00 00 02 6F 03
					15 00 00 40 00 00 02 B5 83
					15 00 00 40 00 00 02 6F 00
					39 00 00 40 00 00 04 B8 25 00 00
					15 00 00 40 00 00 02 6F 03
					39 00 00 40 00 00 03 B8 01 0C
					15 00 00 40 00 00 02 6F 05
					39 00 00 40 00 00 04 B8 25 10 00
					15 00 00 40 00 00 02 6F 08
					39 00 00 40 00 00 03 B8 03 FD
					15 00 00 40 00 00 02 6F 0a
					39 00 00 40 00 00 04 B8 25 20 00
					15 00 00 40 00 00 02 6F 0d
					39 00 00 40 00 00 03 B8 00 4F
					15 00 00 40 00 00 02 6F 0f
					39 00 00 40 00 00 04 B8 25 30 00
					15 00 00 40 00 00 02 6F 12
					39 00 00 40 00 00 03 B8 00 4F
					15 00 00 40 00 00 02 6F 14
					39 00 00 40 00 00 04 B8 25 40 00
					15 00 00 40 00 00 02 6F 17
					39 00 00 40 00 00 03 B8 03 FD
					15 00 00 40 00 00 02 6F 23
					39 00 00 40 00 00 04 B8 3E 00 00
					15 00 00 40 00 00 02 6F 26
					39 00 00 40 00 00 03 B8 01 61
					39 00 00 40 00 00 03 81 01 19
					15 00 00 40 00 00 02 17 30
					15 00 00 40 00 00 02 26 00
					15 00 00 40 00 00 02 2F 00
					39 00 00 40 00 00 05 2A 00 00 06 8F
					39 00 00 40 00 00 05 2B 00 00 09 D7
					15 00 00 40 00 00 02 35 00
					15 00 00 40 00 00 02 53 20
					39 00 00 40 00 00 03 51 0D BB
					15 00 00 40 00 00 02 6F 04
					39 00 00 40 00 00 03 51 0D BB
					39 00 00 40 00 00 03 51 00 00
					15 00 00 40 00 00 02 6F 04
					39 00 00 40 00 00 03 51 00 00
					15 00 00 40 00 00 02 6F 08
					15 00 00 40 00 00 02 51 00
					15 00 00 40 00 00 02 90 03
					15 00 00 40 00 00 02 6F 01
					15 00 00 40 00 00 02 90 43
					39 00 00 40 00 00 13 91 AB A8 00 18 C2 00 02 A4 02 CD 00 0B 04 2D 02 BA 10 F0
					39 00 00 40 00 00 06 F0 55 AA 52 08 01
					15 00 00 40 00 00 02 6F 02
					39 00 00 00 00 00 03 C7 00 00
					39 00 00 40 00 00 06 F0 55 AA 52 08 08
					15 00 00 40 00 00 02 B0 03
					39 00 00 40 00 00 05 FF AA 55 A5 81
					15 00 00 40 00 00 02 6F 0A
					15 00 00 40 00 00 02 FD 00
					39 00 00 40 00 00 06 F0 55 AA 52 08 00
					39 00 00 40 00 00 05 BE 47 40 4B 40
					15 00 00 40 00 00 02 6F 26
					39 00 00 40 00 00 08 44 00 01 00 01 02 0A 80
					15 00 00 40 00 00 02 6F 4F
					39 00 00 40 00 00 06 44 0A 7F 00 00 00
					15 00 00 40 00 00 02 6F 63
					15 00 00 40 00 00 02 44 66
					15 00 00 40 00 00 02 6F 15
					15 00 00 40 00 00 02 35 60
					15 00 00 40 00 00 02 6F 16
					15 00 00 40 00 00 02 35 E3
					15 00 00 40 00 00 02 A2 07
					39 00 00 40 00 00 06 F0 55 AA 52 08 00
					15 00 00 40 00 00 02 6F 03
					15 00 00 40 00 00 02 B5 E5
					39 00 00 40 00 00 06 F0 55 AA 52 08 00
					15 00 00 40 00 00 02 6F 5C
					15 00 00 40 00 00 02 D5 04
					15 00 00 40 00 00 02 6F 5D
					39 00 00 40 00 00 07 D5 04 05 07 02 00 00
					15 00 00 40 00 00 02 6F 63
					39 00 00 40 00 00 07 D5 1D 28 59 D0 00 00
					39 00 00 40 00 00 06 F0 55 AA 52 08 07
					15 00 00 40 00 00 02 C0 00
					39 00 00 40 00 00 06 F0 55 AA 52 08 01
					39 00 00 40 00 00 05 D9 C8 10 11 40
					39 00 00 40 00 00 06 F0 55 AA 52 08 08
					15 00 00 40 00 00 02 6F 1C
					39 00 00 40 00 00 09 BF 10 10 00 10 00 00 00 00
					15 00 00 40 00 00 02 6F 24
					39 00 00 40 00 00 09 BF 84 84 80 08 00 00 00 00
					15 00 00 40 00 00 02 6F C1
					39 00 00 40 00 00 09 BF 0F 10 10 13 14 00 00 00
					39 00 00 40 00 00 06 F0 55 AA 52 08 08
					39 00 00 40 00 00 05 E0 01 01 01 01
					15 00 00 40 00 00 02 6F 06
					39 00 00 40 00 00 0E E0 00 00 21 32 43 54 65 76 87 98 99 99 99
					39 00 00 40 00 00 0F E1 04 04 03 03 02 02 02 02 02 00 00 00 02 02
					15 00 00 40 00 00 02 6F 0E
					39 00 00 40 00 00 0F E1 05 0A 0E 10 10 10 07 05 07 07 09 05 05 05
					15 00 00 40 00 00 02 6F 1C
					39 00 00 40 00 00 0F E1 00 00 01 01 01 01 01 01 02 02 02 14 11 03
					15 00 00 40 00 00 02 6F 2A
					39 00 00 40 00 00 0F E1 01 02 0E 05 05 05 05 05 04 02 00 01 02 06
					15 00 00 40 00 00 02 6F 38
					39 00 00 40 00 00 0F E1 03 03 02 02 03 02 03 03 02 01 01 03 07 02
					15 00 00 40 00 00 02 6F 46
					39 00 00 40 00 00 0F E1 01 02 05 05 02 02 02 01 01 02 03 03 0A 09
					15 00 00 40 00 00 02 6F 54
					39 00 00 40 00 00 0F E1 01 02 02 03 03 02 02 02 01 01 01 01 0D 00
					15 00 00 40 00 00 02 6F 62
					39 00 00 40 00 00 0F E1 01 02 02 03 04 04 04 03 02 02 03 02 13 03
					15 00 00 40 00 00 02 6F 70
					39 00 00 40 00 00 0F E1 01 02 02 02 02 06 04 05 08 02 02 14 03 03
					39 00 00 40 00 00 0F E2 0A 14 1D 27 27 27 27 27 37 30 28 1C 1C 1C
					15 00 00 40 00 00 02 6F 0E
					39 00 00 40 00 00 0F E2 06 0D 14 1A 1C 1E 2D 2D 1B 1B 11 11 09 09
					15 00 00 40 00 00 02 6F 1C
					39 00 00 40 00 00 0F E2 03 01 04 05 04 04 03 02 03 03 03 14 14 05
					15 00 00 40 00 00 02 6F 2A
					39 00 00 40 00 00 0F E2 06 10 12 13 14 14 0B 0A 0A 05 05 05 06 08
					15 00 00 40 00 00 02 6F 38
					39 00 00 40 00 00 0F E2 04 09 08 09 09 0A 0A 05 05 03 03 04 0B 09
					15 00 00 40 00 00 02 6F 46
					39 00 00 40 00 00 0F E2 06 08 0A 0A 08 06 04 03 01 02 03 05 0C 0C
					15 00 00 40 00 00 02 6F 54
					39 00 00 40 00 00 0F E2 05 09 07 07 06 06 05 03 02 02 03 02 0C 02
					15 00 00 40 00 00 02 6F 62
					39 00 00 40 00 00 0F E2 06 08 08 06 07 06 05 04 03 03 04 04 14 03
					15 00 00 40 00 00 02 6F 70
					39 00 00 40 00 00 0F E2 03 01 02 05 04 05 05 05 08 03 03 14 05 05
					39 00 00 40 00 00 0F E3 05 0A 0F 14 14 14 14 14 14 14 20 0A 0A 0A
					15 00 00 40 00 00 02 6F 0E
					39 00 00 40 00 00 0F E3 03 06 09 0C 0C 0A 04 04 06 04 06 0A 0B 0B
					15 00 00 40 00 00 02 6F 1C
					39 00 00 40 00 00 0F E3 00 00 01 01 01 00 00 00 00 01 02 14 10 03
					15 00 00 40 00 00 02 6F 2A
					39 00 00 40 00 00 0F E3 00 00 0D 00 00 00 00 00 00 03 06 00 04 05
					15 00 00 40 00 00 02 6F 38
					39 00 00 40 00 00 0F E3 03 02 02 02 04 04 04 04 01 01 01 03 06 05
					15 00 00 40 00 00 02 6F 46
					39 00 00 40 00 00 0F E3 00 00 03 02 00 00 00 00 00 02 06 06 0D 08
					15 00 00 40 00 00 02 6F 54
					39 00 00 40 00 00 0F E3 00 00 00 00 00 00 00 00 00 01 01 01 0C 00
					15 00 00 40 00 00 02 6F 62
					39 00 00 40 00 00 0F E3 00 01 01 02 02 02 02 02 02 02 01 01 14 02
					15 00 00 40 00 00 02 6F 70
					39 00 00 40 00 00 0F E3 00 01 03 03 03 06 07 07 05 01 02 14 02 03
					39 00 00 40 00 00 06 F0 55 AA 52 08 01
					15 00 00 40 00 00 02 6F 06
					15 00 00 40 00 00 02 DD D8
					15 00 00 40 00 00 02 6F 0B
					39 00 00 00 00 00 05 DD 08 DC 08 DC
					39 00 00 40 00 00 06 F0 55 AA 52 08 04
					15 00 00 40 00 00 02 6F 06
					15 00 00 40 00 00 02 B5 00
					39 00 00 40 00 00 05 FF AA 55 A5 81
					15 00 00 40 00 00 02 6F 0C
					15 00 00 40 00 00 02 FD 40
					39 00 00 40 00 00 07 51 00 00 00 00 00 00
					39 00 00 40 00 00 06 A3 83 44 83 C4 83
					39 00 00 40 00 00 06 F0 55 AA 52 08 01
					15 00 00 40 00 00 02 6F 20
					39 00 00 40 00 00 04 D9 C0 C8 11
					39 00 00 40 00 00 06 F0 55 AA 52 08 01
					15 00 00 40 00 00 02 6F 02
					15 00 00 40 00 00 02 E7 8C
					15 00 00 40 00 00 02 6F 07
					15 00 00 40 00 00 02 E7 8C
					15 00 00 40 00 00 02 6F 0C
					15 00 00 40 00 00 02 E7 88
					15 00 00 40 00 00 02 6F 11
					15 00 00 40 00 00 02 E7 00
					39 00 00 40 00 00 06 F0 55 AA 52 08 05
					39 00 00 40 00 00 05 E0 02 00 00 01
					39 00 00 40 00 00 05 E1 02 00 00 00
					05 00 00 00 78 00 01 11
					39 00 00 40 00 00 06 A3 83 44 83 C4 83
					15 00 00 40 00 00 02 6f 05
					39 00 00 40 00 00 0E A3 02 04 B5 02 03 00 06 00 00 00 00 00 00
					15 00 00 40 00 00 02 6f 12
					39 00 00 40 00 00 0E A3 01 00 9D 00 00 AA 00 00 00 00 00 00 00
					15 00 00 40 00 00 02 6f A1
					39 00 00 40 00 00 0E A3 02 04 B5 02 03 00 18 00 00 00 00 00 00
					15 00 00 40 00 00 02 6f AE
					39 00 00 40 00 00 07 A3 01 00 9D 00 00 AA
					05 00 00 00 00 00 01 29
				];
				qcom,mdss-dsi-off-command = [
					15 00 00 00 0A 00 02 28 00
					15 00 00 00 78 00 02 10 00
				];
				qcom,dsi-panel-date-switch-command = [
					/*read panel info switch page 3*/
					39 00 00 00 00 00 06 F0 55 AA 52 08 03
				];
				qcom,mdss-dsi-default-switch-page-command = [
					39 00 00 00 00 00 06 F0 55 AA 52 08 00
				];
				qcom,mdss-dsi-lp1-command = [
					39 00 00 40 00 00 06 F0 55 AA 52 08 00
					05 00 00 40 00 00 01 39
					15 00 00 40 00 00 02 6F 04
					39 00 00 00 00 00 03 51 0D BB
				];
				qcom,mdss-dsi-nolp-command = [
					39 00 00 40 00 00 06 F0 55 AA 52 08 00
					05 00 00 40 00 00 01 38
					39 00 00 00 00 00 03 51 00 00
				];
				qcom,mdss-dsi-aod-high-mode-command = [
					39 00 00 40 00 00 06 F0 55 AA 52 08 00
					15 00 00 40 00 00 02 6F 04
					39 00 00 00 00 00 03 51 0D BB
				];
				qcom,mdss-dsi-aod-low-mode-command = [
					39 00 00 40 00 00 06 F0 55 AA 52 08 00
					15 00 00 40 00 00 02 6F 04
					39 00 00 00 00 00 03 51 00 03
				];
				qcom,mdss-dsi-timing-switch-command-state = "dsi_lp_mode";
				qcom,mdss-dsi-on-command-state = "dsi_lp_mode";
				qcom,mdss-dsi-off-command-state = "dsi_lp_mode";
				qcom,dsi-panel-date-switch-command-state = "dsi_lp_mode";
				qcom,mdss-dsi-default-switch-page-command-state = "dsi_lp_mode";

				qcom,compression-mode = "dsc";
				qcom,mdss-dsc-version = <0x12>;
				qcom,mdss-dsc-encoders = <1>;
				qcom,mdss-dsc-slice-height = <24>;
				qcom,mdss-dsc-slice-width = <840>;
				qcom,mdss-dsc-slice-per-pkt = <2>;
				qcom,mdss-dsc-bit-per-component = <10>;
				qcom,mdss-dsc-bit-per-pixel = <8>;
				qcom,mdss-dsc-block-prediction-enable;
			};
		};
	};
};

&soc {
	dsi_panel_XN254_P_D_A0040_dsc_cmd {
		qcom,dsi-display-active;
	};
};

&dsi_panel_XN254_P_D_A0040_dsc_cmd {
	qcom,panel-supply-entries = <&oplus_dsi_panel_custom_pwr_supply>;
	qcom,platform-te-gpio = <&tlmm 86 0>;
	qcom,platform-reset-gpio = <&tlmm 146 0>;
	/* DVDDP 1p3 enable */
	oplus,panel-gpio1 = <&pm8550ve_i_gpios 4 0>;
	/* PMIC SGM3820 enable */
	oplus,panel-gpio2 = <&tlmm 6 0>;

	oplus,panel-reset-position = <0x02>;
	oplus,panel-power-on-sequence = "1", "vddio", "3", "vdd", "3", "gpio1", "3", "vci", "5", "gpio2", "3";
	oplus,panel-power-off-sequence = "1", "gpio2", "3", "vci", "3", "gpio1", "3", "vdd", "3", "vddio", "1";


	/* BRIGHTNESS CONFIG */
	qcom,mdss-dsi-bl-pmic-control-type = "bl_ctrl_dcs";
	qcom,bl-update-flag = "delay_until_first_frame";
	qcom,mdss-dsi-bl-inverted-dbv;
	qcom,mdss-dsi-bl-min-level = <1>;
	qcom,mdss-dsi-bl-max-level = <4094>;
	qcom,mdss-brightness-max-level = <4094>;
	oplus,dsi-bl-normal-max-level = <3515>;
	oplus,dsi-brightness-normal-max-level = <3515>;
	oplus,dsi-dc-backlight-threshold = <1960>;
	oplus,dsi-brightness-default-level = <1638>;


	/* FACTORY CONFIG */
	oplus,mdss-dsi-vendor-name = "A0040";
	oplus,mdss-dsi-manufacture = "P_D";
	oplus,color_vivid_status;

	/* Serial number */
	oplus,dsi-serial-number-enabled;
	oplus,dsi-serial-number-switch-page;
	oplus,dsi-serial-number-index= <0>;
	oplus,dsi-serial-number-reg= <0xDF>;
	oplus,dsi-serial-number-read-count= <7>;
	oplus,dsi-serial-number-base-year = <2021>;

	/*timing switch compatible*/
	oplus,timing_switch_compatible;

	/* ESD CONFIG */
	qcom,esd-check-enabled;
	oplus,esd-check-flag-enabled;
	qcom,mdss-dsi-panel-status-check-mode = "reg_read";
	qcom,mdss-dsi-panel-status-command = [
		06 00 00 00 00 00 01 0A
	];
	qcom,mdss-dsi-panel-status-command-state = "dsi_lp_mode";
	qcom,mdss-dsi-panel-status-value = <
		0x9C
	>;
	qcom,mdss-dsi-panel-status-read-length = <1>;
	oplus,mdss-dsi-panel-status-match-modes = <0x00000000>;

	//oplus,enhance_mipi_strength;
	//oplus,vreg_ctrl_flag;
	/* ofp config */
	oplus,ofp-fp-type = <0x02>;
	oplus,ofp-longrui-aod-config = <0x06>;
	oplus,ofp-need-to-wait-data-before-aod-on;

	oplus,dp-enabled;
	qcom,ulps-enabled;
	qcom,dsi-select-clocks = "pll_byte_clk0", "pll_dsi_clk0";
	oplus,apuir-ic-type = <2>;
	oplus,apuir-gir-seedtype = <4>;
	oplus,apuir-param-from-uirloading;
	oplus,apuir-gamma-icds;
	oplus,apuir-sdc-band;
	oplus,apuir-upnit-ds-list            = <2988  3367  4095>;
	oplus,apuir-lessnit-ds-list          = <3635  4095>;
	oplus,apuir-upnit-index-list         = <38  39  40>;
	oplus,apuir-lessnit-index-list       = <30  31  37>;
	oplus,apuir-modeset-list             = <63  0x11  0x17>;
	oplus,apuir-apl_lhset-list           = <50  51  0xFF  0xFF  0x3F  0x33>;

	qcom,mdss-dsi-display-timings {
		/* FHD+ 120hz 1431.6Mbps */
		timing@sdc_fhd_120 {
			qcom,mdss-dsi-panel-phy-timings = [00 2E 0C 0C 1D 1B 0C 0D 0B 02 04 00 25 11];
			qcom,display-topology = <1 1 1>,<2 2 1>;
			qcom,default-topology-index = <1>;
		};
		/* FHD+ 60hz 1431.6Mbps */
		timing@sdc_fhd_60 {
			qcom,mdss-dsi-panel-phy-timings = [00 2E 0C 0C 1D 1B 0C 0D 0B 02 04 00 25 11];
			qcom,display-topology = <1 1 1>,<2 2 1>;
			qcom,default-topology-index = <1>;
		};
		/* FHD+ 90hz 1431.6Mbps */
		timing@sdc_fhd_90 {
			qcom,mdss-dsi-panel-phy-timings = [00 2E 0C 0C 1D 1B 0C 0D 0B 02 04 00 25 11];
			qcom,display-topology = <1 1 1>,<2 2 1>;
			qcom,default-topology-index = <1>;
		};
		/* FHD+ 144hz 1431.6Mbps */
		timing@sdc_fhd_144 {
			qcom,mdss-dsi-panel-phy-timings = [00 2E 0C 0C 1D 1B 0C 0D 0B 02 04 00 25 11];
			qcom,display-topology = <1 1 1>,<2 2 1>;
			qcom,default-topology-index = <1>;
		};
	};
};




